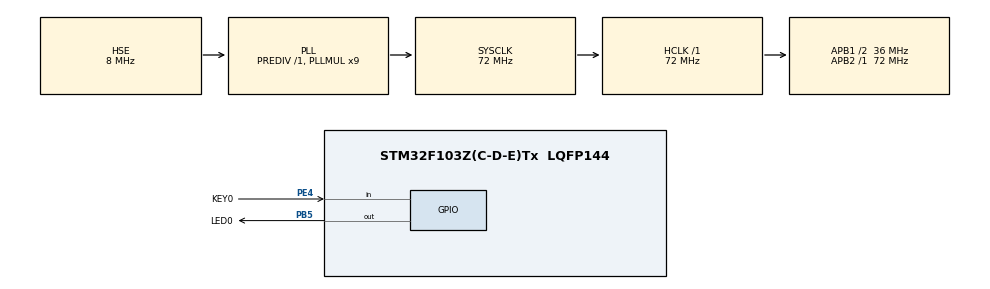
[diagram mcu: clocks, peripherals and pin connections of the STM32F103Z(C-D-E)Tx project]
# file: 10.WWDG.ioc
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Mcu.Family=STM32F1
RCC.PLLSourceVirtual=RCC_PLLSOURCE_HSE
WWDG.Counter=127
RCC.APB1CLKDivider=RCC_HCLK_DIV2
WWDG.EWIMode=WWDG_EWI_ENABLE
RCC.SYSCLKSource=RCC_SYSCLKSOURCE_PLLCLK
ProjectManager.StackSize=0x400
PA13.Signal=SYS_JTMS-SWDIO
ProjectManager.TargetToolchain=STM32CubeIDE
RCC.HCLKFreq_Value=72000000
RCC.APB2TimFreq_Value=72000000
PB5.PinState=GPIO_PIN_SET
OSC_IN.Signal=RCC_OSC_IN
RCC.USBFreq_Value=72000000
OSC_OUT.Mode=HSE-External-Oscillator
OSC_OUT.Signal=RCC_OSC_OUT
RCC.AHBFreq_Value=72000000
board=custom
RCC.PLLMUL=RCC_PLL_MUL9
RCC.APB2Freq_Value=72000000
PA14.Mode=Serial_Wire
PE4.GPIO_Label=KEY0
PA13.Mode=Serial_Wire
PE4.Signal=GPIO_Input
Mcu.Name=STM32F103Z(C-D-E)Tx
PE4.GPIO_PuPd=GPIO_PULLUP
NVIC.WWDG_IRQn=true\:0\:0\:false\:false\:true\:true\:true
RCC.SYSCLKFreq_VALUE=72000000
PB5.Signal=GPIO_Output
Mcu.Package=LQFP144
OSC_IN.Mode=HSE-External-Oscillator
PB5.GPIO_PuPd=GPIO_PULLUP
PA14.Signal=SYS_JTCK-SWCLK
ProjectManager.HeapSize=0x200
VP_WWDG_VS_WWDG.Mode=WWDG_Activate
PB5.GPIO_Speed=GPIO_SPEED_FREQ_HIGH
NVIC.PriorityGroup=NVIC_PRIORITYGROUP_4
PB5.GPIO_Label=LED0
RCC.APB1TimFreq_Value=72000000
WWDG.Window=95
RCC.APB1Freq_Value=36000000
WWDG.Prescaler=WWDG_PRESCALER_8

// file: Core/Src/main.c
/* USER CODE BEGIN Header */
/**
  ******************************************************************************
  * @file           : main.c
  * @brief          : Main program body
  ******************************************************************************
  * @attention
  *
  * <h2><center>&copy; Copyright (c) 2021 STMicroelectronics.
  * All rights reserved.</center></h2>
  *
  * This software component is licensed by ST under BSD 3-Clause license,
  * the "License"; You may not use this file except in compliance with the
  * License. You may obtain a copy of the License at:
  *                        opensource.org/licenses/BSD-3-Clause
  *
  ******************************************************************************
  */
/* USER CODE END Header */
#include "main.h"
#include "wwdg.h"
#include "gpio.h"

void SystemClock_Config(void);

/* USER CODE BEGIN 0 */
void HAL_WWDG_EarlyWakeupCallback(WWDG_HandleTypeDef *hwwdg)
{
	HAL_WWDG_Refresh(hwwdg);
	HAL_GPIO_TogglePin(LED0_GPIO_Port, LED0_Pin);
}
/* USER CODE END 0 */

int main(void)
{

  /* MCU Configuration--------------------------------------------------------*/

  /* Reset of all peripherals, Initializes the Flash interface and the Systick. */
  HAL_Init();

  /* Configure the system clock */
  SystemClock_Config();

  /* Initialize all configured peripherals */
  MX_GPIO_Init();

  /* USER CODE BEGIN 2 */
  HAL_GPIO_WritePin(LED0_GPIO_Port, LED0_Pin, GPIO_PIN_RESET);
  HAL_Delay(300);
  MX_WWDG_Init();
  /* USER CODE END 2 */

  /* Infinite loop */
  while (1)
  {
	  HAL_GPIO_WritePin(LED0_GPIO_Port, LED0_Pin, GPIO_PIN_SET);
  }
}

void SystemClock_Config(void)
{
  RCC_OscInitTypeDef RCC_OscInitStruct = {0};
  RCC_ClkInitTypeDef RCC_ClkInitStruct = {0};

  /** Initializes the RCC Oscillators according to the specified parameters
  * in the RCC_OscInitTypeDef structure.
  */
  RCC_OscInitStruct.OscillatorType = RCC_OSCILLATORTYPE_HSE;
  RCC_OscInitStruct.HSEState = RCC_HSE_ON;
  RCC_OscInitStruct.HSEPredivValue = RCC_HSE_PREDIV_DIV1;
  RCC_OscInitStruct.HSIState = RCC_HSI_ON;
  RCC_OscInitStruct.PLL.PLLState = RCC_PLL_ON;
  RCC_OscInitStruct.PLL.PLLSource = RCC_PLLSOURCE_HSE;
  RCC_OscInitStruct.PLL.PLLMUL = RCC_PLL_MUL9;
  if (HAL_RCC_OscConfig(&RCC_OscInitStruct) != HAL_OK)
  {
    Error_Handler();
  }
  /** Initializes the CPU, AHB and APB buses clocks
  */
  RCC_ClkInitStruct.ClockType = RCC_CLOCKTYPE_HCLK|RCC_CLOCKTYPE_SYSCLK
                              |RCC_CLOCKTYPE_PCLK1|RCC_CLOCKTYPE_PCLK2;
  RCC_ClkInitStruct.SYSCLKSource = RCC_SYSCLKSOURCE_PLLCLK;
  RCC_ClkInitStruct.AHBCLKDivider = RCC_SYSCLK_DIV1;
  RCC_ClkInitStruct.APB1CLKDivider = RCC_HCLK_DIV2;
  RCC_ClkInitStruct.APB2CLKDivider = RCC_HCLK_DIV1;

  if (HAL_RCC_ClockConfig(&RCC_ClkInitStruct, FLASH_LATENCY_2) != HAL_OK)
  {
    Error_Handler();
  }
}

void Error_Handler(void)
{
  __disable_irq();
  while (1)
  {
  }
}

/************************ (C) COPYRIGHT STMicroelectronics *****END OF FILE****/
